# CY8C5888LTI_LP097 register map
File version: 0.1
CY8C58LP
Registers are 8-bit, read-write, no defined reset value unless marked. A register's access mark holds for its fields unless they carry their own. Offsets are from the block's base; lines under a group give offsets from that group; [hi:lo] are bit positions; {n}, {i} and the like mark numbered series; 'fields as' and 'values as' point back to an identical list; <NAME> marks a mode.

## Memory map
0x00000000 AccelerometerTimer
0x00000000 WheelTickTimer
0x00000000 SPI_slave
0x00000000 MotorLockTimer
0x00000000 UART_1 — UART

## AccelerometerTimer
Base 0x00000000
0x40006504 AccelerometerTimer_COUNTER 24-bit — UDB.A0 - Current Down Counter Value
0x40006524 AccelerometerTimer_PERIOD 24-bit — UDB.D0 - Assigned Period
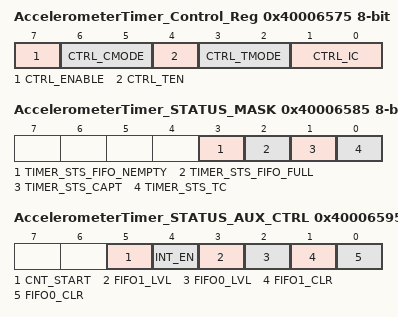
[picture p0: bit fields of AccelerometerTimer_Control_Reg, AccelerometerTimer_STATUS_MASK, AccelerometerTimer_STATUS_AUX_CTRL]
0x40006575 AccelerometerTimer_Control_Reg — UDB Control Register - Assigned Control Register Value
  [7] CTRL_ENABLE — Enable the Timer
  [6:5] CTRL_CMODE — Capture Mode
  [4] CTRL_TEN — Trigger Enable Bit
  [3:2] CTRL_TMODE — Trigger Mode
  [1:0] CTRL_IC — Interrupt Count
0x40006585 AccelerometerTimer_STATUS_MASK — UDB Status bits Interrupt Mask Enable Register
  [3] TIMER_STS_FIFO_NEMPTY ro — FIFO Empty status
  [2] TIMER_STS_FIFO_FULL ro — FIFO Full Status
  [1] TIMER_STS_CAPT ro — Enables the Interrupt on Capture
  [0] TIMER_STS_TC ro — Enables the Interrupt on TC
0x40006595 AccelerometerTimer_STATUS_AUX_CTRL — UDB Auxilliary Control Register
  [5] CNT_START — FIFO0 clear
    0=E_CNT_START0 (Disable counter); 1=E_CNT_START1 (Enable counter)
  [4] INT_EN
    0=E_INT_EN0 (Interrupt disabled); 1=E_INT_EN1 (Interrupt enabled)
  [3] FIFO1_LVL — FIFO level
    0=E_FIFO_LVL_0 (FIFO LVL: input mode: FIFO not full; output mode: FIFO not empty); 1=E_FIFO_LVL_1 (FIFO LVL: input mode: FIFO at least 1/2 empty; output mode: FIFO at least 1/2 full)
  [2] FIFO0_LVL — FIFO level
    values as FIFO1_LVL
  [1] FIFO1_CLR — FIFO1 clear
    0=E_FIFO_CLR_0 (Normal FIFO operation); 1=E_FIFO_CLR_1 (Clear FIFO state)
  [0] FIFO0_CLR — FIFO0 clear
    values as FIFO1_CLR

## WheelTickTimer
Base 0x00000000
0x40006404 WheelTickTimer_COUNTER 16-bit — UDB.A0 - Current Down Counter Value
0x40006424 WheelTickTimer_PERIOD 16-bit — UDB.D0 - Assigned Period
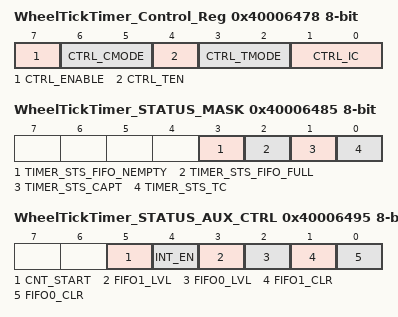
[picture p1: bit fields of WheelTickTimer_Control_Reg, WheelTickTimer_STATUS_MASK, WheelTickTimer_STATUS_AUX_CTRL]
0x40006478 WheelTickTimer_Control_Reg — UDB Control Register - Assigned Control Register Value
  [7] CTRL_ENABLE — Enable the Timer
  [6:5] CTRL_CMODE — Capture Mode
  [4] CTRL_TEN — Trigger Enable Bit
  [3:2] CTRL_TMODE — Trigger Mode
  [1:0] CTRL_IC — Interrupt Count
0x40006485 WheelTickTimer_STATUS_MASK — UDB Status bits Interrupt Mask Enable Register
  fields as AccelerometerTimer.AccelerometerTimer_STATUS_MASK
0x40006495 WheelTickTimer_STATUS_AUX_CTRL — UDB Auxilliary Control Register
  fields as AccelerometerTimer.AccelerometerTimer_STATUS_AUX_CTRL

## SPI_slave
Base 0x00000000
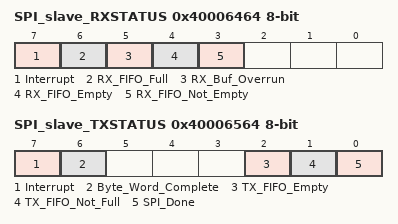
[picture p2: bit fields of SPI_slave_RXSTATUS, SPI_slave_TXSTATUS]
0x40006464 SPI_slave_RXSTATUS — SPIS RX Status Register
  [7] Interrupt ro — Set when interrupt occurs
  [6] RX_FIFO_Full ro — Set when the RX Data FIFO is full
  [5] RX_Buf_Overrun ro — Set when RX Data has overrun the 4 byte/word FIFO without being moved to the RX buffer cmemory array (if one exists)
  [4] RX_FIFO_Empty ro — Set when the RX Data FIFO is empty
  [3] RX_FIFO_Not_Empty ro — Set when the RX Data FIFO is not empty. That is, at least one byte/word is in the RX FIFO
0x40006507 SPI_slave_TX_DATA — SPIS TX Data
0x40006507 SPI_slave_RX_DATA — SPIS RX Data
0x40006564 SPI_slave_TXSTATUS — SPIS TX Status Register
  [7] Interrupt ro — Set when interrupt occurs
  [6] Byte_Word_Complete ro — Set when a byte/word transmit has completed
  [2] TX_FIFO_Empty ro — Set when the TX Data FIFO is empty
  [1] TX_FIFO_Not_Full ro — Set when the TX Data FIFO is not full
  [0] SPI_Done ro — Set when all of the data in the transmit FIFO has been sent. Set when Byte/Word Complete has been set and TX Data FIFO is empty

## MotorLockTimer
Base 0x00000000
0x4000640C MotorLockTimer_COUNTER 16-bit — UDB.A0 - Current Down Counter Value
0x4000642C MotorLockTimer_PERIOD 16-bit — UDB.D0 - Assigned Period
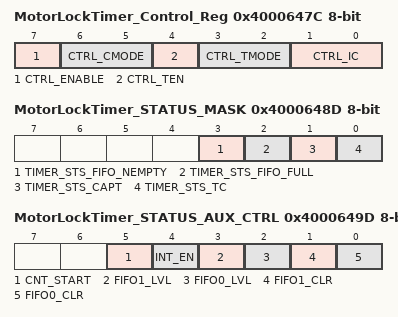
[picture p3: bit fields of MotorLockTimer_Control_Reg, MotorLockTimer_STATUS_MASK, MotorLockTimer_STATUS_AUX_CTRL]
0x4000647C MotorLockTimer_Control_Reg — UDB Control Register - Assigned Control Register Value
  [7] CTRL_ENABLE — Enable the Timer
  [6:5] CTRL_CMODE — Capture Mode
  [4] CTRL_TEN — Trigger Enable Bit
  [3:2] CTRL_TMODE — Trigger Mode
  [1:0] CTRL_IC — Interrupt Count
0x4000648D MotorLockTimer_STATUS_MASK — UDB Status bits Interrupt Mask Enable Register
  fields as AccelerometerTimer.AccelerometerTimer_STATUS_MASK
0x4000649D MotorLockTimer_STATUS_AUX_CTRL — UDB Auxilliary Control Register
  fields as AccelerometerTimer.AccelerometerTimer_STATUS_AUX_CTRL

## UART_1 — UART
Base 0x00000000
0x40006449 TX_UART_1_TX_DATA — TX Data Register
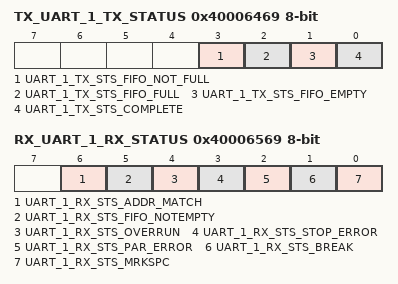
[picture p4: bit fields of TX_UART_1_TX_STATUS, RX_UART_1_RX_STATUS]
0x40006469 TX_UART_1_TX_STATUS — TX status register
  [3] UART_1_TX_STS_FIFO_NOT_FULL ro, [2] UART_1_TX_STS_FIFO_FULL ro, [1] UART_1_TX_STS_FIFO_EMPTY ro, [0] UART_1_TX_STS_COMPLETE ro
0x40006528 RX_UART_1_RX_ADDRESS1 — RX Address1 Register
0x40006538 RX_UART_1_RX_ADDRESS2 — RX Address2 Register
0x40006548 RX_UART_1_RX_DATA — RX Data Register
0x40006569 RX_UART_1_RX_STATUS — RX status register
  [6] UART_1_RX_STS_ADDR_MATCH ro, [5] UART_1_RX_STS_FIFO_NOTEMPTY ro, [4] UART_1_RX_STS_OVERRUN ro, [3] UART_1_RX_STS_STOP_ERROR ro, [2] UART_1_RX_STS_PAR_ERROR ro, [1] UART_1_RX_STS_BREAK ro, [0] UART_1_RX_STS_MRKSPC ro
